# apollo2 register map
Vendor: Ambiq Micro; Series: Apollo; File version: 1.0
Ultra-Low power ARM Cortex-M4 MCU from Ambiq Micro
CPU: CM4 r1p0, little endian, MPU, FPU, 3 interrupt priority bits
Registers are 32-bit, read-write, reset 0x0 unless marked. A register's access mark holds for its fields unless they carry their own. Offsets are from the block's base; lines under a group give offsets from that group; [hi:lo] are bit positions; {n}, {i} and the like mark numbered series; 'fields as' and 'values as' point back to an identical list; <NAME> marks a mode.

## Memory map
0x40000000 RSTGEN size 0x210 — MCU Reset Generator
0x40004000 CLKGEN size 0x110 — Clock Generator
0x40004040 RTC size 0xD0 — Real Time Clock
0x40008000 CTIMER size 0x310 — Counter/Timer
0x4000C000 VCOMP size 0x210 — Voltage Comparator
0x40010000 GPIO size 0x220 — General Purpose IO
0x40018000 CACHECTRL size 0x240 — Flash Cache Controller
0x4001C000 UART0 size 0x48 — Serial UART
0x4001D000 UART1 size 0x48
0x40020000 MCUCTRL size 0x34C — MCU Miscellaneous Control Logic
0x40021000 PWRCTRL size 0x24 — PWR Controller Register Bank
0x40024000 WDT size 0x210 — Watchdog Timer
0x50000000 IOSLAVE size 0x220 — I2C/SPI Slave
0x50004000 IOMSTR0 size 0x308 — I2C/SPI Master
0x50005000 IOMSTR1 size 0x308
0x50006000 IOMSTR2 size 0x308
0x50007000 IOMSTR3 size 0x308
0x50008000 IOMSTR4 size 0x308
0x50009000 IOMSTR5 size 0x308
0x50010000 ADC size 0x210 — Analog Digital Converter Control
0x50011000 PDM size 0x210 — PDM Audio

## Interrupts
0 BROWNOUT (MCUCTRL)
1 WDT
2 CLKGEN_RTC (CLKGEN)
3 VCOMP
4 IOSLAVE
5 IOSLAVEACC (IOSLAVE)
6 IOMSTR0
7 IOMSTR1
8 IOMSTR2
9 IOMSTR3
10 IOMSTR4
11 IOMSTR5
12 GPIO
13 CTIMER
14 UART0
15 UART1
16 ADC
17 PDM
18 STIMER (CTIMER)
{n+19} STIMER_CMPR{n} (CTIMER) (n=0..7)

## RSTGEN — MCU Reset Generator
Base 0x40000000
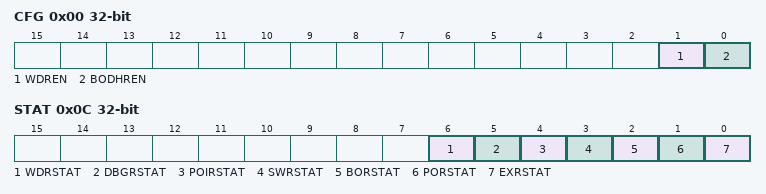
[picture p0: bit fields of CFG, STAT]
0x00 CFG — Configuration Register
  [1] WDREN — Watchdog Timer Reset Enable. NOTE: The WDT module must also be configured for WDT reset.
  [0] BODHREN — Brown out high (2.1v) reset enable.
0x04 SWPOI — Software POI Reset
  [7:0] SWPOIKEY — 0x1B generates a software POI reset.
    27=KEYVALUE (Writing 0x1B key value generates a software POI reset. value.)
0x08 SWPOR — Software POR Reset
  [7:0] SWPORKEY — 0xD4 generates a software POR reset.
    212=KEYVALUE (Writing 0xD4 key value generates a software POR reset. value.)
0x0C STAT — Status Register
  [6] WDRSTAT — Reset was initiated by a Watchdog Timer Reset.
  [5] DBGRSTAT — Reset was a initiated by Debugger Reset.
  [4] POIRSTAT — Reset was a initiated by Software POI Reset.
  [3] SWRSTAT — Reset was a initiated by SW POR or AIRCR Reset.
  [2] BORSTAT — Reset was initiated by a Brown-Out Reset.
  [1] PORSTAT — Reset was initiated by a Power-On Reset.
  [0] EXRSTAT — Reset was initiated by an External Reset.
0x10 CLRSTAT — Clear the status register
  [0] CLRSTAT — Writing a 1 to this bit clears all bits in the RST_STAT.
0x14 TPIU_RST — TPIU reset
  [0] TPIURST — Static reset for the TPIU. Write to '1' to assert reset to TPIU. Write to '0' to clear the reset.
0x200 INTEN — Reset Interrupt register: Enable
  [0] BODH — Enables an interrupt that triggers when VCC is below BODH level.
0x204 INTSTAT — Reset Interrupt register: Status
  fields as INTEN
0x208 INTCLR — Reset Interrupt register: Clear
  fields as INTEN
0x20C INTSET — Reset Interrupt register: Set
  fields as INTEN

## Licence text in the file
Copyright (C) 2015-2017, Ambiq Micro. All rights reserved. . Redistribution and use in source and binary forms, with or without modification, are permitted provided that the following conditions are met: . 1. Redistributions of source code must retain the above copyright notice, this list of conditions and the following disclaimer. . 2. Redistributions in binary form must reproduce the above copyright notice, this list of conditions and the following disclaimer in the documentation and/or other materials provided with the distribution. . 3. Neither the name of the copyright holder nor the names of itscontributors may be used to endorse or promote products derived from thissoftware without specific prior written permission. . THIS SOFTWARE IS PROVIDED BY THE COPYRIGHT HOLDERS AND CONTRIBUTORS "AS IS" AND ANY EXPRESS OR IMPLIED WARRANTIES, INCLUDING, BUT NOT LIMITED TO, THE. IMPLIED WARRANTIES OF MERCHANTABILITY AND FITNESS FOR A PARTICULAR PURPOSE. ARE DISCLAIMED. IN NO EVENT SHALL THE COPYRIGHT HOLDER OR CONTRIBUTORS BE. LIABLE FOR ANY DIRECT, INDIRECT, INCIDENTAL, SPECIAL, EXEMPLARY, OR. CONSEQUENTIAL DAMAGES (INCLUDING, BUT NOT LIMITED TO, PROCUREMENT OF. SUBSTITUTE GOODS OR SERVICES; LOSS OF USE, DATA, OR PROFITS; OR BUSINESS. INTERRUPTION) HOWEVER CAUSED AND ON ANY THEORY OF LIABILITY, WHETHER IN. CONTRACT, STRICT LIABILITY, OR TORT (INCLUDING NEGLIGENCE OR OTHERWISE). ARISING IN ANY WAY OUT OF THE USE OF THIS SOFTWARE, EVEN IF ADVISED OF THE. POSSIBILITY OF SUCH DAMAGE.

## Notices in the file
Copyright (C) 2012-2014 ARM Limited. All rights reserved.
Purpose: System Viewer Description (SVD) Example (Schema Version 1.1)
This is a description of a none-existent and incomplete device
for demonstration purposes only.
- Neither the name of ARM nor the names of its contributors may be used
ARE DISCLAIMED. IN NO EVENT SHALL COPYRIGHT HOLDERS AND CONTRIBUTORS BE
